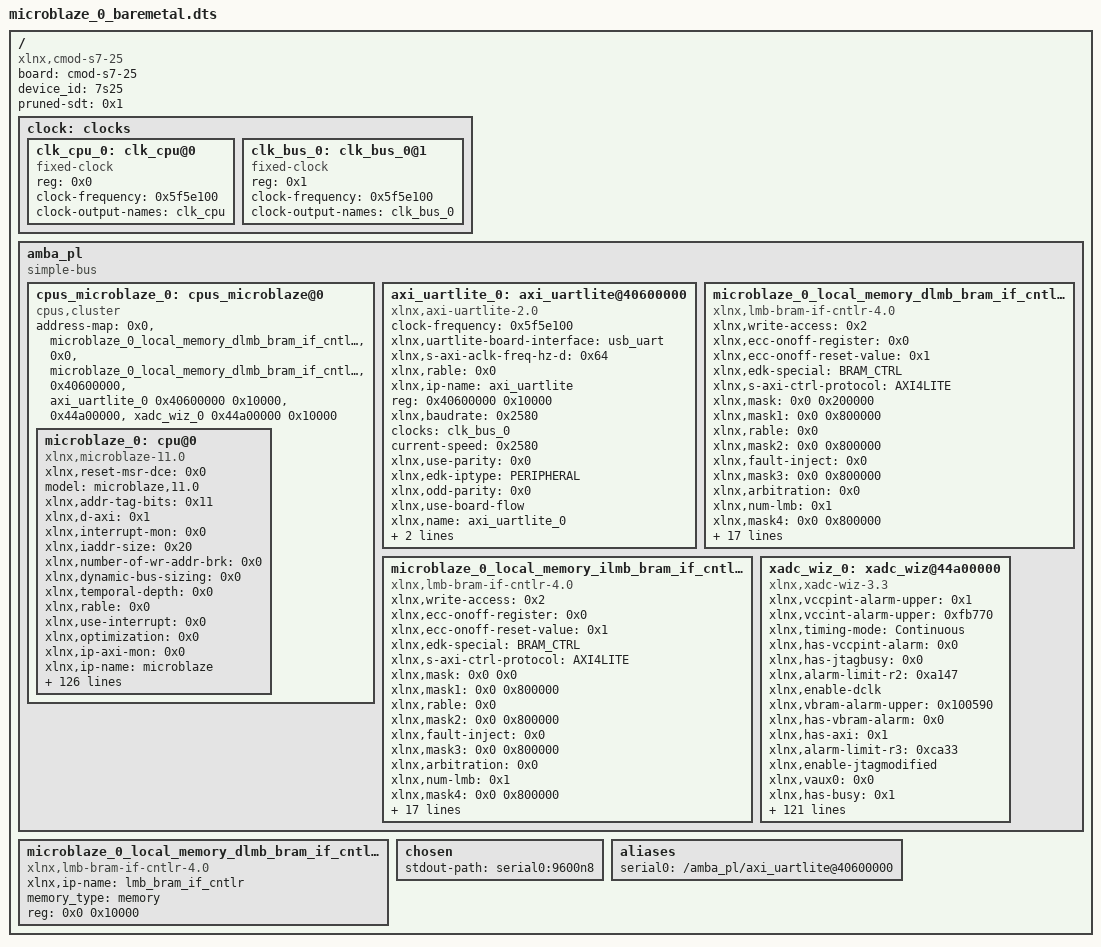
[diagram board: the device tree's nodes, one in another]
/dts-v1/;

/ {
        board = "cmod-s7-25";
        compatible = "xlnx,cmod-s7-25";
        device_id = "7s25";
        #address-cells = <0x1>;
        #size-cells = <0x1>;
        pruned-sdt = <0x1>;

        clock: clocks {
                #address-cells = <0x1>;
                #size-cells = <0x0>;
                phandle = <0x7>;

                clk_cpu_0: clk_cpu@0 {
                        compatible = "fixed-clock";
                        reg = <0x0>;
                        clock-frequency = <0x5f5e100>;
                        clock-output-names = "clk_cpu";
                        #clock-cells = <0x0>;
                        phandle = <0x8>;
                };

                clk_bus_0: clk_bus_0@1 {
                        compatible = "fixed-clock";
                        reg = <0x1>;
                        clock-frequency = <0x5f5e100>;
                        clock-output-names = "clk_bus_0";
                        #clock-cells = <0x0>;
                        phandle = <0x6>;
                };
        };

        amba_pl: amba_pl {
                ranges;
                compatible = "simple-bus";
                #address-cells = <0x1>;
                #size-cells = <0x1>;
                phandle = <0x5>;

                cpus_microblaze_0: cpus_microblaze@0 {
                        #cpu-mask-cells = <0x1>;
                        compatible = "cpus,cluster";
                        #address-cells = <0x1>;
                        #size-cells = <0x0>;
                        address-map = <0x0 &microblaze_0_local_memory_dlmb_bram_if_cntlr_memory 0x0 0x10000>,
                         <0x0 &microblaze_0_local_memory_dlmb_bram_if_cntlr 0x0 0x10000>,
                         <0x40600000 &axi_uartlite_0 0x40600000 0x10000>,
                         <0x44a00000 &xadc_wiz_0 0x44a00000 0x10000>;
                        #ranges-address-cells = <0x1>;
                        #ranges-size-cells = <0x1>;
                        phandle = <0x9>;

                        microblaze_0: cpu@0 {
                                xlnx,reset-msr-dce = <0x0>;
                                model = "microblaze,11.0";
                                xlnx,addr-tag-bits = <0x11>;
                                xlnx,d-axi = <0x1>;
                                xlnx,interrupt-mon = <0x0>;
                                xlnx,iaddr-size = <0x20>;
                                xlnx,number-of-wr-addr-brk = <0x0>;
                                xlnx,dynamic-bus-sizing = <0x0>;
                                xlnx,temporal-depth = <0x0>;
                                xlnx,rable = <0x0>;
                                xlnx,use-interrupt = <0x0>;
                                xlnx,optimization = <0x0>;
                                xlnx,ip-axi-mon = <0x0>;
                                xlnx,ip-name = "microblaze";
                                d-cache-highaddr = <0x3fffffff>;
                                xlnx,dcache-force-tag-lutram = <0x0>;
                                xlnx,pc-width = <0x20>;
                                xlnx,interrupt-is-edge = <0x0>;
                                reg = <0x0>;
                                xlnx,async-interrupt = <0x1>;
                                xlnx,use-mmu = <0x0>;
                                xlnx,reset-msr-ee = <0x0>;
                                xlnx,icache-victims = <0x0>;
                                xlnx,use-reorder-instr = <0x1>;
                                xlnx,d-lmb-mon = <0x0>;
                                xlnx,d-lmb-protocol = <0x0>;
                                xlnx,ill-opcode-exception = <0x0>;
                                xlnx,dcache-always-used = <0x1>;
                                xlnx,use-div = <0x0>;
                                xlnx,dc-axi-mon = <0x0>;
                                xlnx,debug-trace-async-reset = <0x0>;
                                xlnx,trace = <0x0>;
                                xlnx,part = "xc7s25csga225-1";
                                i-cache-baseaddr = <0x0>;
                                xlnx,use-config-reset = <0x0>;
                                xlnx,pvr = <0x0>;
                                xlnx,i-lmb-mon = <0x0>;
                                xlnx,dcache-byte-size = <0x2000>;
                                xlnx,fault-tolerant = <0x0>;
                                xlnx,family = "spartan7";
                                compatible = "xlnx,microblaze-11.0", "xlnx,microblaze";
                                xlnx,data-size = <0x20>;
                                xlnx,mmu-zones = <0x10>;
                                xlnx,debug-trace-size = <0x2000>;
                                xlnx,mmu-privileged-instr = <0x0>;
                                xlnx,enable-discrete-ports = <0x0>;
                                d-cache-line-size = <0x10>;
                                xlnx,d-lmb = <0x1>;
                                xlnx,sco = <0x0>;
                                xlnx,reset-msr-eip = <0x0>;
                                clock-frequency = <0x5f5e100>;
                                xlnx,debug-interface = <0x0>;
                                xlnx,use-ext-brk = <0x0>;
                                xlnx,daddr-size = <0x20>;
                                xlnx,debug-enabled = <0x1>;
                                xlnx,reset-msr-ice = <0x0>;
                                xlnx,num-sync-ff-dbg-trace-clk = <0x2>;
                                xlnx,i-lmb-protocol = <0x0>;
                                xlnx,endianness = <0x1>;
                                xlnx,fsl-exception = <0x0>;
                                i-cache-line-size = <0x10>;
                                xlnx,use-extended-fsl-instr = <0x0>;
                                xlnx,reset-msr = <0x0>;
                                xlnx,dp-axi-mon = <0x0>;
                                xlnx,branch-target-cache-size = <0x0>;
                                xlnx,dcache-use-writeback = <0x0>;
                                xlnx,div-zero-exception = <0x0>;
                                xlnx,mmu-tlb-access = <0x3>;
                                bus-handle = <0x5>;
                                xlnx,cache-byte-size = <0x2000>;
                                xlnx,pvr-user2 = <0x0>;
                                xlnx,opcode-0x0-illegal = <0x0>;
                                xlnx,icache-line-len = <0x4>;
                                xlnx,ecc-use-ce-exception = <0x0>;
                                xlnx,base-vectors = <0x0 0x0>;
                                xlnx,use-dcache = <0x0>;
                                xlnx,use-barrel = <0x0>;
                                xlnx,reset-msr-bip = <0x0>;
                                xlnx,edk-special = "microblaze";
                                xlnx,allow-dcache-wr = <0x1>;
                                xlnx,addr-size = <0x20>;
                                xlnx,debug-external-trace = <0x0>;
                                xlnx,piaddr-size = <0x20>;
                                i-cache-highaddr = <0x3fffffff>;
                                xlnx,num-sync-ff-clk-debug = <0x2>;
                                xlnx,debug-event-counters = <0x5>;
                                xlnx,fpu-exception = <0x0>;
                                xlnx,allow-icache-wr = <0x1>;
                                xlnx,i-axi = <0x0>;
                                xlnx,g-use-exceptions = <0x0>;
                                xlnx,icache-streams = <0x0>;
                                xlnx,g-template-list = <0x0>;
                                xlnx,dcache-line-len = <0x4>;
                                xlnx,num-sync-ff-clk = <0x2>;
                                xlnx,use-stack-protection = <0x0>;
                                xlnx,use-hw-mul = <0x0>;
                                xlnx,num-sync-ff-dbg-clk = <0x1>;
                                xlnx,interconnect = <0x2>;
                                xlnx,edk-iptype = "PROCESSOR";
                                i-cache-size = <0x2000>;
                                xlnx,debug-latency-counters = <0x1>;
                                xlnx,use-fpu = <0x0>;
                                xlnx,reset-msr-ie = <0x0>;
                                xlnx,edge-is-positive = <0x1>;
                                xlnx,use-pcmp-instr = <0x0>;
                                xlnx,use-icache = <0x0>;
                                d-cache-size = <0x2000>;
                                xlnx,async-wakeup = <0x3>;
                                xlnx,use-non-secure = <0x0>;
                                xlnx,dcache-addr-tag = <0x11>;
                                xlnx,number-of-rd-addr-brk = <0x0>;
                                d-cache-baseaddr = <0x0>;
                                xlnx,area-optimized = <0x0>;
                                xlnx,avoid-primitives = <0x0>;
                                xlnx,lockstep-slave = <0x0>;
                                xlnx,use-ext-nm-brk = <0x0>;
                                xlnx,instr-size = <0x20>;
                                xlnx,icache-always-used = <0x1>;
                                xlnx,i-lmb = <0x1>;
                                xlnx,mmu-dtlb-size = <0x4>;
                                xlnx,lockstep-select = <0x0>;
                                xlnx,lmb-data-size = <0x20>;
                                xlnx,ic-axi-mon = <0x0>;
                                xlnx,enable-conversion = <0x1>;
                                xlnx,num-sync-ff-clk-irq = <0x1>;
                                xlnx,fsl-links = <0x0>;
                                timebase-frequency = <0x5f5e100>;
                                xlnx,icache-force-tag-lutram = <0x0>;
                                xlnx,dcache-data-width = <0x0>;
                                xlnx,dcache-victims = <0x0>;
                                xlnx,use-branch-target-cache = <0x0>;
                                xlnx,debug-profile-size = <0x0>;
                                xlnx,unaligned-exceptions = <0x0>;
                                xlnx,lockstep-master = <0x0>;
                                xlnx,freq = <0x5f5e100>;
                                xlnx,number-of-pc-brk = <0x1>;
                                xlnx,mmu-itlb-size = <0x2>;
                                xlnx,imprecise-exceptions = <0x0>;
                                xlnx,use-msr-instr = <0x0>;
                                xlnx,icache-data-width = <0x0>;
                                xlnx,debug-counter-width = <0x20>;
                                phandle = <0xa>;
                        };
                };

                axi_uartlite_0: axi_uartlite@40600000 {
                        compatible = "xlnx,axi-uartlite-2.0", "xlnx,xps-uartlite-1.00.a";
                        clock-frequency = <0x5f5e100>;
                        xlnx,uartlite-board-interface = "usb_uart";
                        xlnx,s-axi-aclk-freq-hz-d = <0x64>;
                        xlnx,rable = <0x0>;
                        xlnx,ip-name = "axi_uartlite";
                        reg = <0x40600000 0x10000>;
                        xlnx,baudrate = <0x2580>;
                        clocks = <&clk_bus_0>;
                        current-speed = <0x2580>;
                        xlnx,use-parity = <0x0>;
                        xlnx,edk-iptype = "PERIPHERAL";
                        xlnx,odd-parity = <0x0>;
                        status = "okay";
                        xlnx,use-board-flow;
                        xlnx,name = "axi_uartlite_0";
                        xlnx,data-bits = <0x8>;
                        xlnx,parity = "No_Parity";
                        phandle = <0x3>;
                };

                microblaze_0_local_memory_dlmb_bram_if_cntlr: lmb_bram_if_cntlr@0 {
                        xlnx,write-access = <0x2>;
                        compatible = "xlnx,lmb-bram-if-cntlr-4.0";
                        xlnx,ecc-onoff-register = <0x0>;
                        xlnx,ecc-onoff-reset-value = <0x1>;
                        xlnx,edk-special = "BRAM_CTRL";
                        xlnx,s-axi-ctrl-protocol = "AXI4LITE";
                        xlnx,mask = <0x0 0x200000>;
                        xlnx,mask1 = <0x0 0x800000>;
                        xlnx,rable = <0x0>;
                        xlnx,mask2 = <0x0 0x800000>;
                        xlnx,fault-inject = <0x0>;
                        xlnx,mask3 = <0x0 0x800000>;
                        xlnx,arbitration = <0x0>;
                        xlnx,num-lmb = <0x1>;
                        xlnx,mask4 = <0x0 0x800000>;
                        reg = <0x0 0x10000>;
                        xlnx,s-axi-ctrl-addr-width = <0x20>;
                        xlnx,mask5 = <0x0 0x800000>;
                        xlnx,ecc-status-registers = <0x0>;
                        xlnx,mask6 = <0x0 0x800000>;
                        xlnx,lmb-protocol = <0x0>;
                        xlnx,ce-counter-width = <0x0>;
                        xlnx,mask7 = <0x0 0x800000>;
                        xlnx,ecc = <0x0>;
                        xlnx,lmb-dwidth = <0x20>;
                        xlnx,interconnect = <0x0>;
                        xlnx,ce-failing-registers = <0x0>;
                        xlnx,edk-iptype = "PERIPHERAL";
                        xlnx,ue-failing-registers = <0x0>;
                        xlnx,s-axi-ctrl-data-width = <0x20>;
                        xlnx,bram-awidth = <0x20>;
                        xlnx,lmb-awidth = <0x20>;
                        phandle = <0x2>;
                };

                microblaze_0_local_memory_ilmb_bram_if_cntlr: lmb_bram_if_cntlr@1 {
                        xlnx,write-access = <0x2>;
                        compatible = "xlnx,lmb-bram-if-cntlr-4.0";
                        xlnx,ecc-onoff-register = <0x0>;
                        xlnx,ecc-onoff-reset-value = <0x1>;
                        xlnx,edk-special = "BRAM_CTRL";
                        xlnx,s-axi-ctrl-protocol = "AXI4LITE";
                        xlnx,mask = <0x0 0x0>;
                        xlnx,mask1 = <0x0 0x800000>;
                        xlnx,rable = <0x0>;
                        xlnx,mask2 = <0x0 0x800000>;
                        xlnx,fault-inject = <0x0>;
                        xlnx,mask3 = <0x0 0x800000>;
                        xlnx,arbitration = <0x0>;
                        xlnx,num-lmb = <0x1>;
                        xlnx,mask4 = <0x0 0x800000>;
                        reg = <0x0 0x10000>;
                        xlnx,s-axi-ctrl-addr-width = <0x20>;
                        xlnx,mask5 = <0x0 0x800000>;
                        xlnx,ecc-status-registers = <0x0>;
                        xlnx,mask6 = <0x0 0x800000>;
                        xlnx,lmb-protocol = <0x0>;
                        xlnx,ce-counter-width = <0x0>;
                        xlnx,mask7 = <0x0 0x800000>;
                        xlnx,ecc = <0x0>;
                        xlnx,lmb-dwidth = <0x20>;
                        xlnx,interconnect = <0x0>;
                        xlnx,ce-failing-registers = <0x0>;
                        xlnx,edk-iptype = "PERIPHERAL";
                        xlnx,ue-failing-registers = <0x0>;
                        xlnx,s-axi-ctrl-data-width = <0x20>;
                        xlnx,bram-awidth = <0x20>;
                        xlnx,lmb-awidth = <0x20>;
                        phandle = <0xb>;
                };

                xadc_wiz_0: xadc_wiz@44a00000 {
                        xlnx,vccpint-alarm-upper = <0x1>;
                        xlnx,vccint-alarm-upper = <0xfb770>;
                        xlnx,timing-mode = "Continuous";
                        xlnx,has-vccpint-alarm = <0x0>;
                        xlnx,has-jtagbusy = <0x0>;
                        xlnx,alarm-limit-r2 = <0xa147>;
                        xlnx,enable-dclk;
                        xlnx,vbram-alarm-upper = <0x100590>;
                        xlnx,has-vbram-alarm = <0x0>;
                        xlnx,has-axi = <0x1>;
                        xlnx,alarm-limit-r3 = <0xca33>;
                        xlnx,enable-jtagmodified;
                        xlnx,vaux0 = <0x0>;
                        xlnx,has-busy = <0x1>;
                        xlnx,alarm-limit-r4 = <0xa93a>;
                        xlnx,vaux1 = <0x0>;
                        xlnx,has-vccaux-alarm = <0x0>;
                        xlnx,alarm-limit-r5 = <0x52c6>;
                        xlnx,dclk-frequency = <0x64>;
                        xlnx,enable-channel;
                        xlnx,vaux2 = <0x0>;
                        xlnx,rable = <0x0>;
                        xlnx,alarm-limit-r6 = <0x9555>;
                        xlnx,vaux3 = <0x0>;
                        xlnx,has-drp = <0x0>;
                        xlnx,ip-name = "xadc_wiz";
                        xlnx,alarm-limit-r7 = <0xae4e>;
                        xlnx,configuration-r0 = <0x1000>;
                        xlnx,vaux4 = <0x0>;
                        xlnx,sim-file-rel-path = "./";
                        reg = <0x44a00000 0x10000>;
                        xlnx,alarm-limit-r8 = <0x5999>;
                        xlnx,configuration-r1 = <0x21af>;
                        xlnx,external-mux-channel = "VP_VN";
                        xlnx,vaux5 = <0x1>;
                        xlnx,temperature-alarm-trigger = <0x55>;
                        xlnx,has-jtaglocked = <0x0>;
                        xlnx,alarm-limit-r9 = <0x5111>;
                        xlnx,c-component-name = "design_1_xadc_wiz_0_0";
                        xlnx,configuration-r2 = <0x400>;
                        xlnx,vaux6 = <0x0>;
                        xlnx,vaux7 = <0x0>;
                        xlnx,channel-enable-vauxp12-vauxn12;
                        xlnx,vaux8 = <0x0>;
                        xlnx,vaux9 = <0x0>;
                        xlnx,vaux10 = <0x0>;
                        xlnx,has-vn = <0x1>;
                        xlnx,has-vccpaux-alarm = <0x0>;
                        xlnx,acquisition-time = <0x4>;
                        xlnx,vaux11 = <0x0>;
                        xlnx,has-temp-bus = <0x0>;
                        xlnx,xadc-starup-selection = "channel_sequencer";
                        xlnx,vaux12 = <0x1>;
                        xlnx,sim-file-sel = "Default";
                        xlnx,has-vp = <0x1>;
                        xlnx,data-width = <0x20>;
                        xlnx,enable-busy;
                        xlnx,ip-type = <0x0>;
                        xlnx,vaux13 = <0x0>;
                        xlnx,temperature-alarm-ot-reset = <0x46>;
                        xlnx,vaux14 = <0x0>;
                        xlnx,enable-convst;
                        xlnx,vccpaux-alarm-lower = <0x1a17b0>;
                        xlnx,vccaux-alarm-lower = <0x1ab3f0>;
                        xlnx,vaux15 = <0x0>;
                        compatible = "xlnx,xadc-wiz-3.3", "xlnx,axi-xadc-1.00.a";
                        xlnx,has-external-mux = <0x0>;
                        xlnx,sampling-rate = <0x7fffffff>;
                        xlnx,has-reset = <0x0>;
                        xlnx,adc-conversion-rate = <0x3e8>;
                        clock-frequency = <0x5f5e100>;
                        xlnx,vccddro-alarm-lower = <0x118c30>;
                        xlnx,has-user-temp-alarm = <0x0>;
                        xlnx,enable-calibration-averaging;
                        xlnx,has-ot-alarm = <0x0>;
                        xlnx,has-convst = <0x0>;
                        xlnx,single-channel-selection = "TEMPERATURE";
                        xlnx,startup-channel-selection = "single_channel";
                        xlnx,interface-selection = "Enable_AXI";
                        xlnx,vccpaux-alarm-upper = <0x1b7740>;
                        xlnx,vccaux-alarm-upper = <0x1cd6d0>;
                        status = "okay";
                        xlnx,sensor-offset-and-gain-calibration;
                        xlnx,vccddro-alarm-upper = <0x1312d0>;
                        xlnx,name = "xadc_wiz_0";
                        xlnx,external-mux = "none";
                        xlnx,enable-eoc;
                        xlnx,sim-file-name = "design";
                        xlnx,enable-jtaglocked;
                        xlnx,temperature-alarm-reset = <0x3c>;
                        xlnx,addr-width = <0x20>;
                        clocks = <&clk_bus_0>;
                        xlnx,alarm-limit-r10 = <0x5555>;
                        xlnx,alarm-limit-r11 = <0x5111>;
                        xlnx,alarm-limit-r12 = <0x9999>;
                        xlnx,alarm-limit-r13 = <0x91eb>;
                        xlnx,edk-iptype = "PERIPHERAL";
                        xlnx,sequencer-mode = "Continuous";
                        xlnx,alarm-limit-r14 = <0x6aaa>;
                        xlnx,enable-jtagbusy;
                        xlnx,include-intr = <0x1>;
                        xlnx,fifo-depth = <0x7>;
                        xlnx,alarm-limit-r15 = <0x6222>;
                        xlnx,has-eoc = <0x1>;
                        xlnx,temperature-alarm-ot-trigger = <0x7d>;
                        xlnx,has-channel = <0x1>;
                        xlnx,enable-eos;
                        xlnx,vccpint-alarm-lower = <0xe7ef0>;
                        xlnx,vccint-alarm-lower = <0xecd10>;
                        xlnx,has-dclk = <0x1>;
                        xlnx,vbram-alarm-lower = <0xe7ef0>;
                        xlnx,sequence-r0 = <0x0>;
                        xlnx,num-wave = <0x1>;
                        xlnx,has-jtagmodified = <0x0>;
                        xlnx,sequence-r1 = <0x1020>;
                        xlnx,sequence-r2 = <0x0>;
                        xlnx,has-vccint-alarm = <0x0>;
                        xlnx,channel-averaging = <0x10>;
                        xlnx,enable-drp;
                        xlnx,sequence-r3 = <0x0>;
                        xlnx,has-axi4stream = <0x0>;
                        xlnx,sequence-r4 = <0x0>;
                        xlnx,sequence-r5 = <0x0>;
                        xlnx,adc-offset-and-gain-calibration;
                        xlnx,waveform-type = "CONSTANT";
                        xlnx,sequence-r6 = <0x0>;
                        xlnx,vccddro-volt = "1_2";
                        xlnx,sequence-r7 = <0x0>;
                        xlnx,channel-enable-vauxp5-vauxn5;
                        xlnx,has-vccddro-alarm = <0x0>;
                        xlnx,has-eos = <0x1>;
                        xlnx,has-convstclk = <0x0>;
                        xlnx,alarm-limit-r0 = <0xb5ed>;
                        xlnx,stimulus-freq = <0x1>;
                        xlnx,single-channel-enable-calibration;
                        xlnx,alarm-limit-r1 = <0x57e4>;
                        xlnx,external-muxaddr-enable = <0x0>;
                        phandle = <0x4>;
                };
        };

        microblaze_0_local_memory_dlmb_bram_if_cntlr_memory: memory@0 {
                compatible = "xlnx,lmb-bram-if-cntlr-4.0";
                xlnx,ip-name = "lmb_bram_if_cntlr";
                device_type = "memory";
                memory_type = "memory";
                reg = <0x0 0x10000>;
                phandle = <0x1>;
        };

        chosen {
                stdout-path = "serial0:9600n8";
        };

        aliases {
                serial0 = "/amba_pl/axi_uartlite@40600000";
        };

        __symbols__ {
                clock = "/clocks";
                clk_cpu_0 = "/clocks/clk_cpu@0";
                clk_bus_0 = "/clocks/clk_bus_0@1";
                amba_pl = "/amba_pl";
                cpus_microblaze_0 = "/amba_pl/cpus_microblaze@0";
                microblaze_0 = "/amba_pl/cpus_microblaze@0/cpu@0";
                axi_uartlite_0 = "/amba_pl/axi_uartlite@40600000";
                microblaze_0_local_memory_dlmb_bram_if_cntlr = "/amba_pl/lmb_bram_if_cntlr@0";
                microblaze_0_local_memory_ilmb_bram_if_cntlr = "/amba_pl/lmb_bram_if_cntlr@1";
                xadc_wiz_0 = "/amba_pl/xadc_wiz@44a00000";
                microblaze_0_local_memory_dlmb_bram_if_cntlr_memory = "/memory@0";
        };
};
